# N32F030 register map
File version: 1.0
Registers are 32-bit, read-write, reset 0x0 unless marked. A register's access mark holds for its fields unless they carry their own. Offsets are from the block's base; [hi:lo] are bit positions.

## UI2C1 — UI2C Register Map
Base 0x40170000; alternate view of UUART1
0x00 UI2C_CTL — USCI Control Register
  [2:0] FUNMODE — Function Mode. This bit field selects the protocol for this USCI controller. Selecting a protocol that is not available or a reserved combination disables the USCI. When switching between two protocols, the USCI has to be disabled before selecting a new protocol. Simultaneously, the USCI will be reset when user write 000 to FUNMODE. Note: Other bit combinations are reserved.
    0=The USCI is disabled. All protocol related state machines are set to idle state; 1=The SPI protocol is selected; 2=The UART protocol is selected; 4=The I2C protocol is selected
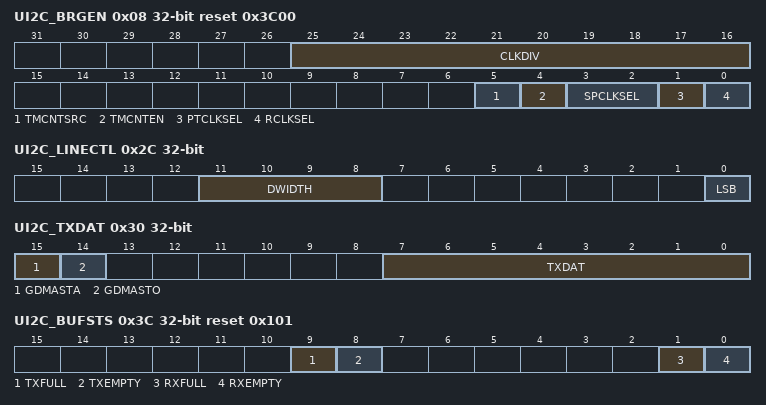
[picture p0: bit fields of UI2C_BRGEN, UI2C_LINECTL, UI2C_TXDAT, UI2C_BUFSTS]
0x08 UI2C_BRGEN reset 0x3C00 — USCI Baud Rate Generator Register
  [25:16] CLKDIV — Clock Divider. Note: In UART function, it can be updated by hardware in the 4th falling edge of the input data 0x55 when the auto baud rate function (ABREN(UI2C_PROTCTL[6])) is enabled. The revised value is the average bit time between bit 5 and bit 6. The user can use revised CLKDIV and new BRDETITV (UI2C_PROTCTL[24:16]) to calculate the precise baud rate.
  [5] TMCNTSRC — Time Measurement Counter Clock Source Selection. In I2C mode, this bit need clear to 0 to do timeout measurement counter with fPCLK.
  [4] TMCNTEN — Time Measurement Counter Enable Bit. This bit enables the 10-bit timing measurement counter.
    0=Time measurement counter for timeout function is Disabled; 1=Time measurement counter for timeout function is Enabled
  [3:2] SPCLKSEL — Sample Clock Source Selection. This bit field used for the clock source selection of a sample clock (fSAMP_CLK) for the protocol processor.
    0=fSAMP_CLK = fDIV_CLK; 1=fSAMP_CLK = fPROT_CLK; 2=fSAMP_CLK = fSCLK; 3=fSAMP_CLK = fREF_CLK
  [1] PTCLKSEL — Protocol Clock Source Selection. This bit selects the source signal of protocol clock (fPROT_CLK).
    0=Reference clock fREF_CLK; 1=fREF_CLK2 (its frequency is half of fREF_CLK)
  [0] RCLKSEL — Reference Clock Source Selection. This bit selects the source signal of reference clock (fREF_CLK).
    0=Peripheral device clock fPCLK; 1=External input clock
0x2C UI2C_LINECTL — USCI Line Control Register
  [11:8] DWIDTH — Word Length of Transmission. This bit field defines the data word length (amount of bits) for reception and transmission. The data word is always right-aligned in the data buffer. USCI support word length from 4 to 16 bits. 0x0: The data word contains 16 bits located at bit positions [15:0]. 0x1: Reserved. 0x2: Reserved. 0x3: Reserved. 0x4: The data word contains 4 bits located at bit positions [3:0]. 0x5: The data word contains 5 bits located at bit positions [4:0]. ... 0xF: The data word contains 15 bits located at bit positions [14:0]. Note: In I2C protocol, the length must be configured as 8 bits.
  [0] LSB — LSB First Transmission Selection
    0=The MSB, which bit of transmit/receive data buffer depends on the setting of DWIDTH, is transmitted/received first; 1=The LSB, the bit 0 of data buffer, will be transmitted/received first
0x30 UI2C_TXDAT wo — USCI Transmit Data Register
  [15] GDMASTA — I2C START Control (for GDMA only). Setting STA to logic 1 to enter Master mode, the I2C hardware sends a START or repeat START condition to bus when the bus is free.
  [14] GDMASTO — I2C STOP Control (for GDMA only)
  [7:0] TXDAT — Transmit Data. Software can use this bit field to write 8-bit transmit data for transmission.
0x34 UI2C_RXDAT ro — USCI Receive Data Register
  [15:0] RXDAT — Received Data. This bit field monitors the received data which stored in receive data buffer. Note 1: In I2C protocol, only use RXDAT[7:0].
0x3C UI2C_BUFSTS ro reset 0x101 — USCI Transmit/Receive Buffer Status Register
  [9] TXFULL — Transmit Buffer Full Indicator
    0=Transmit buffer is not full; 1=Transmit buffer is full
  [8] TXEMPTY — Transmit Buffer Empty Indicator
    0=Transmit buffer is not empty; 1=Transmit buffer is empty
  [1] RXFULL — Receive Buffer Full Indicator
    0=Receive buffer is not full; 1=Receive buffer is full
  [0] RXEMPTY — Receive Buffer Empty Indicator
    0=Receive buffer is not empty; 1=Receive buffer is empty
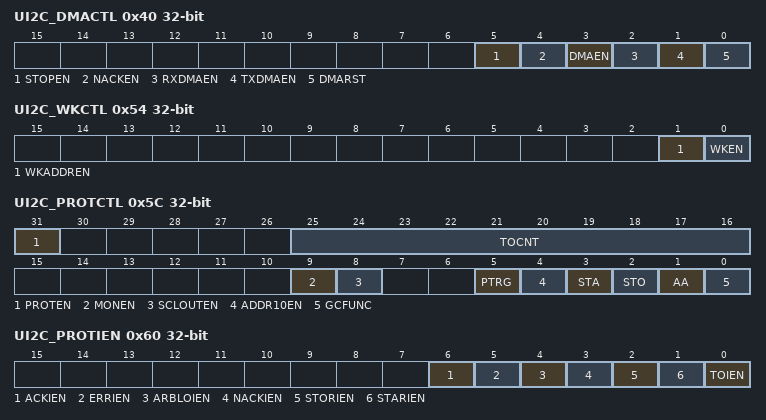
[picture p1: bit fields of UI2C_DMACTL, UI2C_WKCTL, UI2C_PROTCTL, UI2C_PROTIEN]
0x40 UI2C_DMACTL — USCI DMA Control Register
  [5] STOPEN — 1: When finish of RXDAM in master mode, hardware will auto generate STOP condition
  [4] NACKEN — 1: When finish of RXDAM in slave mode, hardware will auto NACK the last byte.
  [3] DMAEN — DMA Mode Enable Bit
    0=DMA function Disabled; 1=DMA function Enabled
  [2] RXDMAEN — DMA Receive Channel Request Enable
    0=Receive DMA function Disabled; 1=Receive DMA function Enabled
  [1] TXDMAEN — DMA Transmit Channel Request Enable
    0=Transmit DMA function Disabled; 1=Transmit DMA function Enabled
  [0] DMARST — DMA Reset
    0=No effect; 1=Reset the USCI's DMA control logic. This bit will be cleared to 0 automatically
0x44 UI2C_DEVADDR0 — USCI Device Address Register 0
  [9:0] DEVADDR — Device Address. In I2C protocol, this bit field contains the programmed slave address. If the first received address byte is b1111 0AAX, the AA bits are compared to the bits DEVADDR[9:8] to check for address match, where the X is R/W bit. Then the second address byte is also compared to DEVADDR[7:0]. Note: When I2C operating in 7-bit address mode, only use DEVADDR[6:0]
0x4C UI2C_ADDRMSK0 — USCI Device Address Mask Register 0
  [9:0] ADDRMSK — USCI Device Address Mask. USCI support multiple address recognition with two address mask register. When the bit in the address mask register is set to one, it means the received corresponding address bit is don't-care. If the bit is set to 0, that means the received corresponding register bit should be exact the same as address register.
    0=Mask Disabled (the received corresponding register bit should be exact the same as address register.); 1=Mask Enabled (the received corresponding address bit is don't care.)
0x54 UI2C_WKCTL — USCI Wake-up Control Register
  [1] WKADDREN — Wake-up Address Match Enable Bit
    0=The chip is woken up according to data toggle; 1=The chip is woken up according to address match
  [0] WKEN — Wake-up Enable Bit
    0=Wake-up function Disabled; 1=Wake-up function Enabled
0x58 UI2C_WKSTS — USCI Wake-up Status Register
  [0] WKF — Wake-up Flag. When chip is woken up from Power-down mode, this bit is set to 1. Software can write 1 to clear this bit.
0x5C UI2C_PROTCTL — USCI Protocol Control Register
  [31] PROTEN — I2C Protocol Enable Bit
    0=I2C Protocol disable; 1=I2C Protocol enable
  [25:16] TOCNT — Time-out Clock Cycle. This bit field indicates how many clock cycle selected by TMCNTSRC (UI2C_BRGEN [5]) when each interrupt flags are clear. The time-out is enable when TOCNT bigger than 0. Note: The TMCNTSRC (UI2C_BRGEN [5]) must be set zero on I2C mode.
  [9] MONEN — I2C Monitor Enable Bit
    0=I2C Monitor disable; 1=I2C Monitor enable
  [8] SCLOUTEN — SCL Output Enable Bit
    0=SCL output force high disable; 1=SCL output force high enable
  [5] PTRG — I2C Protocol Trigger. When a new state is present in the UI2C_PROTSTS register, if the related interrupt enable bits are set, the I2C interrupt is requested. It must write one by software to this bit after the related interrupt flags are set to 1 and the I2C protocol function will go ahead until the STOP is active or the PROTEN is disabled.
    0=I2C's stretch disabled and the I2C protocol function will go ahead; 1=I2C's stretch active
  [4] ADDR10EN — Address 10-bit Function Enable Bit
    0=Address match 10 bit function is disabled; 1=Address match 10 bit function is enabled
  [3] STA — I2C START Control. Setting STA to logic 1 to enter Master mode, the I2C hardware sends a START or repeat START condition to bus when the bus is free.
  [2] STO — I2C STOP Control
  [1] AA — Assert Acknowledge Control
  [0] GCFUNC — General Call Function
    0=General Call Function Disabled; 1=General Call Function Enabled
0x60 UI2C_PROTIEN — USCI Protocol Interrupt Enable Register
  [6] ACKIEN — Acknowledge Interrupt Enable Control. This bit enables the generation of a protocol interrupt if an acknowledge is detected by a master.
    0=The acknowledge interrupt is disabled; 1=The acknowledge interrupt is enabled
  [5] ERRIEN — Error Interrupt Enable Control. This bit enables the generation of a protocol interrupt if an I2C error condition is detected (indicated by ERR (UI2C_PROTSTS [16])).
    0=The error interrupt is disabled; 1=The error interrupt is enabled
  [4] ARBLOIEN — Arbitration Lost Interrupt Enable Control. This bit enables the generation of a protocol interrupt if an arbitration lost event is detected.
    0=The arbitration lost interrupt is disabled; 1=The arbitration lost interrupt is enabled
  [3] NACKIEN — Non - Acknowledge Interrupt Enable Control. This bit enables the generation of a protocol interrupt if a non - acknowledge is detected by a master.
    0=The non - acknowledge interrupt is disabled; 1=The non - acknowledge interrupt is enabled
  [2] STORIEN — Stop Condition Received Interrupt Enable Control. This bit enables the generation of a protocol interrupt if a stop condition is detected.
    0=The stop condition interrupt is disabled; 1=The stop condition interrupt is enabled
  [1] STARIEN — Start Condition Received Interrupt Enable Control. This bit enables the generation of a protocol interrupt if a start condition is detected.
    0=The start condition interrupt is disabled; 1=The start condition interrupt is enabled
  [0] TOIEN — Time-out Interrupt Enable Control. In I2C protocol, this bit enables the interrupt generation in case of a time-out event.
    0=The time-out interrupt is disabled; 1=The time-out interrupt is enabled
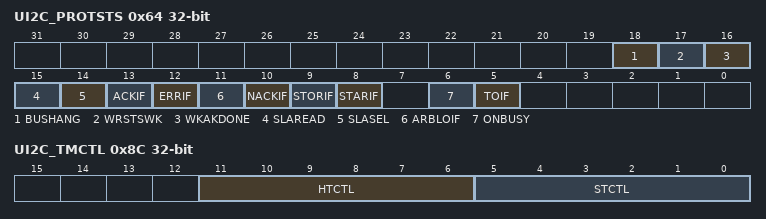
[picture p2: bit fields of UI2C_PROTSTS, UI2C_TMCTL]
0x64 UI2C_PROTSTS — USCI Protocol Status Register
  [18] BUSHANG — Bus Hang-up. This bit indicates bus hang-up status. There is 4-bit counter count when SCL hold high and refer fSAMP_CLK. The hang-up counter will count to overflow and set this bit when SDA is low. The counter will be reset by falling edge of SCL signal. Note: This bit has no interrupt signal, and it will be cleared automatically by hardware.
    0=The bus is normal status for transmission; 1=The bus is hang-up status for transmission
  [17] WRSTSWK — Read/Write Status Bit in Address Wakeup Frame
    0=Write command be record on the address match wakeup frame; 1=Read command be record on the address match wakeup frame
  [16] WKAKDONE — Wakeup Address Frame Acknowledge Bit Done. Note: This bit can't release when WKUPIF is set.
    0=The ACK bit cycle of address match frame isn't done; 1=The ACK bit cycle of address match frame is done in power-down
  [15] SLAREAD — Slave Read Request Status. This bit indicates that a slave read request has been detected. Note: This bit has no interrupt signal, and it will be cleared automatically by hardware.
    0=A slave read request has not been detected; 1=A slave read request has been detected
  [14] SLASEL — Slave Select Status. This bit indicates that this device has been selected as slave. Note: This bit has no interrupt signal, and it will be cleared automatically by hardware.
    0=The device is not selected as slave; 1=The device is selected as slave
  [13] ACKIF — Acknowledge Received Interrupt Flag. It is cleared by software writing one into this bit
    0=An acknowledge has not been received; 1=An acknowledge has been received
  [12] ERRIF — Error Interrupt Flag. It is cleared by software writing one into this bit. Note: This bit is set when slave mode, user must write one into STO register to the defined 'not addressed' slave mode.
    0=An I2C error has not been detected; 1=An I2C error has been detected
  [11] ARBLOIF — Arbitration Lost Interrupt Flag. It is cleared by software writing one into this bit
    0=An arbitration has not been lost; 1=An arbitration has been lost
  [10] NACKIF — Non - Acknowledge Received Interrupt Flag. It is cleared by software writing one into this bit. Note: When this bit is set, the master will generate a stop bit in next transmation, so MCU needs to clear it before transmition.
    0=A non - acknowledge has not been received; 1=A non - acknowledge has been received
  [9] STORIF — Stop Condition Received Interrupt Flag. It is cleared by software writing one into this bit
    0=A stop condition has not yet been detected; 1=A stop condition has been detected
  [8] STARIF — Start Condition Received Interrupt Flag. This bit indicates that a start condition or repeated start condition has been detected on master mode. However, this bit also indicates that a repeated start condition has been detected on slave mode. It is cleared by software writing one into this bit
    0=A start condition has not yet been detected; 1=A start condition has been detected
  [6] ONBUSY — On Bus Busy. Indicates that a communication is in progress on the bus. It is set by hardware when a START condition is detected. It is cleared by hardware when a STOP condition is detected
    0=The bus is IDLE (both SCLK and SDA High); 1=The bus is busy
  [5] TOIF — Time-out Interrupt Flag. Note: It is cleared by software writing one into this bit
    0=A time-out interrupt status has not occurred; 1=A time-out interrupt status has occurred
0x8C UI2C_TMCTL — I2C Timing Configure Control Register
  [11:6] HTCTL — Hold Time Configure Control Register. This field is used to generate the delay timing between SCL falling edge SDA edge in transmission mode.
  [5:0] STCTL — Setup Time Configure Control Register. This field is used to generate a delay timing between SDA edge and SCL rising edge in transmission mode.

## UI2C2 — UI2C Register Map
Base 0x40270000; alternate view of UUART2
Registers as UI2C1.
